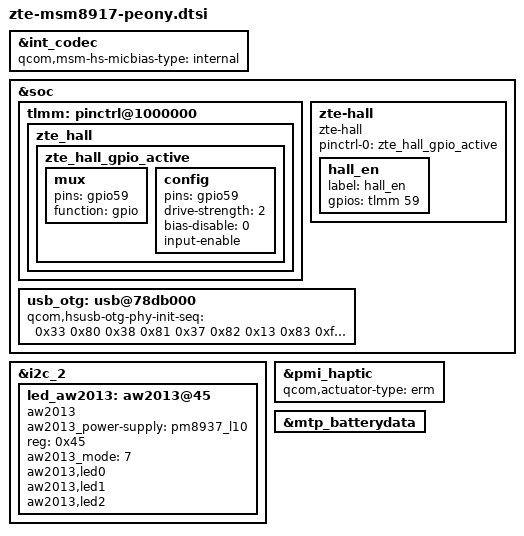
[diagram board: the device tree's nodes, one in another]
/*
 * device tree for zte peony board
 */

#include "dsi-panel-zte-dijing-nt35521-cmi-5p5-720p-video.dtsi"
#include "dsi-panel-zte-lead-ili9881c-cpt-5p5-720p-video.dtsi"
#include "dsi-panel-zte-tianma-s6d7aa6-tm-5p5-720p-video.dtsi"
#include "dsi-panel-zte-dijing-nt35521sh-auo-5p5-720p-video.dtsi"
#include "touch-key-backlight-peony.dtsi"

#include "msm8917-camera-sensor-peony.dtsi"

&int_codec {
	qcom,msm-hs-micbias-type = "internal";
};
&soc {
	tlmm: pinctrl@1000000 {
		zte_hall: zte_hall {
			zte_hall_gpio_active: zte_hall_gpio_active {
				mux {
					pins = "gpio59";
					function = "gpio";
				};
				config {
					pins = "gpio59";
					drive-strength = <2>; /* 2 mA */
					bias-disable = <0>; /* no pull */
					input-enable; /* input */
				};
			};
		};
	};
};

&soc {
	zte-hall {
		compatible = "zte-hall";
		pinctrl-names = "zte_hall_gpio_active";
		pinctrl-0 = <&zte_hall_gpio_active>;
		hall_en{
			label = "hall_en";
			gpios = <&tlmm 59 0x0>;
		};
	};
};

&i2c_2 {
	led_aw2013:aw2013@45 {
		aw2013_power-supply = <&pm8937_l10>;
		compatible = "aw2013";
		reg = <0x45>;
		status = "ok";
		aw2013_mode = < 7 >;
	};
};

&led_aw2013 {
	aw2013,led0;
	aw2013,led1;
	aw2013,led2;
};

&pmi_haptic {
	status = "okay";
	qcom,actuator-type = "erm";
};

&mtp_batterydata {
	#include "zte_p817a22_3250mah.dtsi"
	#include "zte_P817a22cos_3320mAh.dtsi"
};

/* ZTE, USB phy init seq override, wangzy*/
&soc {
	usb_otg: usb@78db000 {
		qcom,hsusb-otg-phy-init-seq =
			<0x33 0x80 0x38 0x81 0x37 0x82 0x13 0x83 0xffffffff>;
	};
};
